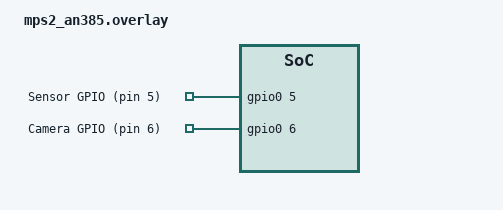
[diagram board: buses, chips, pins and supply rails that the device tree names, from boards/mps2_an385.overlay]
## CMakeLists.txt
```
cmake_minimum_required(VERSION 3.13.1)

find_package(Zephyr REQUIRED HINTS $ENV{ZEPHYR_BASE})
project(embedded_systems_project)

target_sources(app PRIVATE
    src/main.c
    src/ipc.c
    src/sensors.c
    src/controller.c
    src/camera.c
    src/display_dummy.c
    src/input_thread.c
    tests/integration/vehicle_simulator.c
)
```

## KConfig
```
# Kconfig - Radar System Configuration

menu "Configuração de Sistema de Radar"

config RADAR_SENSOR_DISTANCE_MM
    int "Distância entre os sensores (MM)"
    default 500
    range 100 2000
    help
      Distancia entre os dois sensores magnéticos usados para calcular a velocidade.

config RADAR_SPEED_LIMIT_LIGHT_KMH
    int "Limite de velocidade para veículos leves (km/h)"
    default 60
    range 30 100
    help
      Velocidade máxima permitida para veículos leves (2 eixos).

config RADAR_SPEED_LIMIT_HEAVY_KMH
    int "Limite de Velocidade para veículos pesados (km/h)"
    default 40
    range 20 80
    help
      Velocidade máxima permitida para veículos pesados (3+ eixos).

config RADAR_WARNING_THRESHOLD_PERCENT
    int "Percentual de limite de velocidade que dispara o aviso"
    default 90
    range 80 99
    help
      Percentual de limite de velocidade que aciona o aviso amarelo na tela.

config RADAR_CAMERA_FAILURE_RATE_PERCENT
    int "Taxa de simulaçao de Falha da Camera (0-100%)"
    default 10
    range 0 100
    help
      Porcetagem de chance da camera simular uma falha.
```

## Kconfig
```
menu "Zephyr"
source "Kconfig.zephyr"


config RADAR_SENSOR_DISTANCE_MM
    int "Distância entre os sensores (MM)"
    default 500
    range 100 2000
    help
      Distancia entre os dois sensores magnéticos usados para calcular a velocidade.

config RADAR_SPEED_LIMIT_LIGHT_KMH
    int "Limite de velocidade para veículos leves (km/h)"
    default 110
    range 30 120
    help
      Velocidade máxima permitida para veículos leves (2 eixos).

config RADAR_SPEED_LIMIT_HEAVY_KMH
    int "Limite de Velocidade para veículos pesados (km/h)"
    default 95
    range 40 100
    help
      Velocidade máxima permitida para veículos pesados (3+ eixos).

config RADAR_WARNING_THRESHOLD_PERCENT
    int "Percentual de limite de velocidade que dispara o aviso"
    default 10
    range 0 100
    help
      Percentual de limite de velocidade que aciona o aviso amarelo na tela.

config RADAR_CAMERA_FAILURE_RATE_PERCENT
    int "Taxa de simulaçao de Falha da Camera (0-100%)"
    default 10
    range 0 100
    help
      Percentagem de chance da camera simular uma falha.

endmenu
```

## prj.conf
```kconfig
CONFIG_MAIN_STACK_SIZE=2048
CONFIG_SYSTEM_WORKQUEUE_STACK_SIZE=2048

CONFIG_LOG=y
CONFIG_LOG_MODE_MINIMAL=y

CONFIG_PRINTK=y

CONFIG_ASSERT=y

CONFIG_NEWLIB_LIBC=y
CONFIG_POLL=y

CONFIG_SERIAL=y
CONFIG_UART_CONSOLE=y

CONFIG_UART_ASYNC_API=y 

CONFIG_CONSOLE=y
CONFIG_CBPRINTF_FP_SUPPORT=y

CONFIG_RADAR_SENSOR_DISTANCE_MM=500
CONFIG_RADAR_SPEED_LIMIT_LIGHT_KMH=80
CONFIG_RADAR_SPEED_LIMIT_HEAVY_KMH=60
CONFIG_RADAR_WARNING_THRESHOLD_PERCENT=10
CONFIG_RADAR_CAMERA_FAILURE_RATE_PERCENT=10
```

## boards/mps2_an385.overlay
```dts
#include <zephyr/dt-bindings/gpio/gpio.h>

/ {
    aliases {
        sensorgpio = &sensor_node;
        cameragpio = &camera_node;
    };

    sensors {
        compatible = "gpio-keys";

        sensor_node: sensor_gpio0 {
            gpios = <&gpio0 5 (GPIO_ACTIVE_HIGH | GPIO_PULL_UP)>;
            label = "Sensor GPIO (pin 5)";
        };

        camera_node: camera_gpio0 {
            gpios = <&gpio0 6 (GPIO_ACTIVE_HIGH | GPIO_PULL_UP)>;
            label = "Camera GPIO (pin 6)";
        };
    };
};
```

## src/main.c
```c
#include <zephyr/kernel.h>
#include <zephyr/logging/log.h>

#include "ipc.h"
#include "sensors.h"
#include "controller.h"
#include "camera.h"     
#include "display_dummy.h" 
#include "../tests/integration/vehicle_simulator.h" 
#include "input_thread.h"    

LOG_MODULE_REGISTER(main_app, LOG_LEVEL_INF);


K_THREAD_DEFINE(sensors_thread_def, 1024, sensors_thread, NULL, NULL, NULL, 
                7, 0, 0);

K_THREAD_DEFINE(controller_thread_def, 2048, controller_thread, NULL, NULL, NULL,
                5, 0, 0);
                
K_THREAD_DEFINE(display_thread_def, 1024, display_dummy_thread, NULL, NULL, NULL,
                6, 0, 0);


int main(void)
{
    LOG_INF("========================================");
    LOG_INF(" Radar Eletrônico - Sistema Iniciado");
    LOG_INF(" Plataforma: mps2_an385 (QEMU)");
    LOG_INF("========================================");

    LOG_INF("Inicializando IPC...");
    ipc_init();  
    LOG_INF("IPC OK.");

    LOG_INF("Inicializando módulos...");

    sensors_init();
    controller_init();
    camera_init();
    display_dummy_init();

    LOG_INF("Todos os módulos foram inicializados.");

    vehicle_simulator_start(); 
    input_thread_start();

    LOG_INF("Sistema operacional ativo. Threads rodando.");
    
   
    while (1) {
        
        k_sleep(K_FOREVER);
    }

    return 0;
}
```

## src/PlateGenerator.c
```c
#include <stdio.h>
#include <stdlib.h>
#include <time.h>

int main()
{
    srand(time(NULL));
    
    char plate[8];
    char alphabet[26] = {'a','b','c','d','e','f','g','h','i','j','k','l','m','n','o','p','q','r','s','t','u','v','w','x','y','z'};

    for (int j = 0; j < 3; j++){
        int index = rand() % 26; 
        plate[j] = alphabet[index];
    }

    int num1 = rand() % 10; 
    plate[3] = num1 + '0'; 

    int index4 = rand() % 26;
    plate[4] = alphabet[index4];
    
    int num5 = rand() % 10;
    plate[5] = num5 + '0'; 
    
    int num6 = rand() % 10;
    plate[6] = num6 + '0';
    
    plate[7] = '\0'; 


        /*
        
        printf("Placa Mercosul Gerada (LLLNLNN): ");
         printf("%c%c%c %c%c%c%c\n", 
           plate[0], plate[1], plate[2], 
           plate[3], plate[4], plate[5], plate[6]);
        */

    return 0;
}
```

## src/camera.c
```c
#include "camera.h"
#include <zephyr/logging/log.h>
#include <zephyr/random/random.h>

LOG_MODULE_REGISTER(camera, LOG_LEVEL_INF);

void camera_init(void)
{
    LOG_INF("Camera inicializada (falha simulada = %d%%)",
            CONFIG_RADAR_CAMERA_FAILURE_RATE_PERCENT);
}

bool camera_process_frame(void)
{
    uint8_t sorte = sys_rand32_get() % 100;

    if (sorte < CONFIG_RADAR_CAMERA_FAILURE_RATE_PERCENT) {
        LOG_WRN("Falha simulada da câmera!");
        return false;
    }

    LOG_INF("Frame capturado com sucesso.");
    return true;
}

void camera_thread(void *a, void *b, void *c)
{
    ARG_UNUSED(a); ARG_UNUSED(b); ARG_UNUSED(c);

    LOG_INF("Thread da câmera iniciada.");

    while (1) {
        camera_process_frame();
        k_sleep(K_SECONDS(2));
    }
}
```

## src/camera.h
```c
#ifndef CAMERA_H
#define CAMERA_H

#include <zephyr/kernel.h>
#include <zephyr/sys/util.h>
#include <stdbool.h>

void camera_init(void);
bool camera_process_frame(void);   
void camera_thread(void *, void *, void *);

#endif
```

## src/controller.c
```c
#include "controller.h"
#include "sensors.h"
#include "ipc.h"                 
#include "../tests/integration/vehicle_simulator.h"   
#include "display_dummy.h"       
#include <zephyr/logging/log.h>
#include <stdio.h>              


LOG_MODULE_REGISTER(controller, LOG_LEVEL_INF);


void controller_init(void)
{
    LOG_INF("Controller inicializado.");
}

float controller_calcula_velocidade_kmh(uint32_t tempo_ms)
{
    if (tempo_ms == 0) return 0.0f;

    float distancia_m = CONFIG_RADAR_SENSOR_DISTANCE_MM / 1000.0f;
    float tempo_s = tempo_ms / 1000.0f;

    float v_mps = distancia_m / tempo_s;
    float v_kmh = v_mps * 3.6f;
    return v_kmh;
}

tipo_veiculo_t controller_classifica_eixos(uint8_t num_eixos)
{
    if (num_eixos <= 2) return VEICULO_LEVE;
    return VEICULO_PESADO;
}

status_t controller_avalia_velocidade(float vel_kmh, tipo_veiculo_t tipo)
{
    float limite = (tipo == VEICULO_LEVE)
        ? CONFIG_RADAR_SPEED_LIMIT_LIGHT_KMH
        : CONFIG_RADAR_SPEED_LIMIT_HEAVY_KMH;

    float tolerancia = limite * (CONFIG_RADAR_WARNING_THRESHOLD_PERCENT / 100.0f);
    float limite_amarelo = limite + tolerancia;

    if (vel_kmh > limite)
    {
        if (vel_kmh <= limite_amarelo)
            return STATUS_AMARELO;

        return STATUS_VERMELHO;
    }

    return STATUS_VERDE;
}


void controller_thread(void *a, void *b, void *c)
{
    ARG_UNUSED(a);
    ARG_UNUSED(b);
    ARG_UNUSED(c);

    LOG_INF("Thread do controller iniciada. Aguardando dados/eventos...");

    struct sensor_msg sensor_msg;
    ipc_msg_t event_msg;
    ipc_msg_t camera_msg; 

    struct k_poll_event events[] = {
        K_POLL_EVENT_INITIALIZER(K_POLL_TYPE_MSGQ_DATA_AVAILABLE, K_POLL_MODE_NOTIFY_ONLY, &sensor_to_controller_msgq),
        K_POLL_EVENT_INITIALIZER(K_POLL_TYPE_MSGQ_DATA_AVAILABLE, K_POLL_MODE_NOTIFY_ONLY, &event_to_controller_msgq),
        K_POLL_EVENT_INITIALIZER(K_POLL_TYPE_MSGQ_DATA_AVAILABLE, K_POLL_MODE_NOTIFY_ONLY, &camera_to_controller_msgq)
    };

    while (1) {
        int ret = k_poll(events, ARRAY_SIZE(events), K_FOREVER);
        
        if (ret < 0) {
            LOG_ERR("Erro no k_poll: %d", ret);
            continue;
        }

        if (events[1].state == K_POLL_STATE_MSGQ_DATA_AVAILABLE) {
            if (k_msgq_get(&event_to_controller_msgq, &event_msg, K_NO_WAIT) == 0) { 

                if (event_msg.type == IPC_EVT_VEHICLE_REQUEST) {
                    
                    LOG_INF("EVENTO: Novo Veículo Acionado pelo Teclado. ID: %d", event_msg.data);

                    vehicle_simulator_press_enter(); 
                    
                    const char* new_plate = vehicle_simulator_generate();
                    
                    char display_text[64];
                    snprintf(display_text, sizeof(display_text), "SIMULATOR TRIGGERED. PLATE: %s", new_plate);
                    display_dummy_show_text(display_text); 
                }
            }
        }


        if (events[0].state == K_POLL_STATE_MSGQ_DATA_AVAILABLE) {
            if (k_msgq_get(&sensor_to_controller_msgq, &sensor_msg, K_NO_WAIT) == 0) {
                
                float vel = controller_calcula_velocidade_kmh(sensor_msg.tempo_ms);
                tipo_veiculo_t tipo = controller_classifica_eixos(sensor_msg.num_eixos);
                status_t status = controller_avalia_velocidade(vel, tipo);
                
                struct display_msg disp_msg = {
                    .vel_kmh = vel,
                    .tipo = tipo,
                    .status = status
                };
                
                if (k_msgq_put(&controller_to_display_msgq, &disp_msg, K_MSEC(50)) != 0) {
                    LOG_ERR("Falha ao enviar mensagem para o Display Dummy!");
                }
                
            
            }

        }

        
        if (events[2].state == K_POLL_STATE_MSGQ_DATA_AVAILABLE) {
            if (k_msgq_get(&camera_to_controller_msgq, &camera_msg, K_NO_WAIT) == 0) {
               
                // Aqui entraria a lógica de Reconhecimento de Placa ou processamento de imagem
                LOG_INF("CAMERA: Nova mensagem recebida. Iniciando processamento de placa...");
                
            }
        }

        for (size_t i = 0; i < ARRAY_SIZE(events); i++) {
            events[i].state = K_POLL_STATE_NOT_READY;
        }
    }
}
```

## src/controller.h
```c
#ifndef CONTROLLER_H
#define CONTROLLER_H

#include <zephyr/kernel.h>
#include <stdbool.h>
#include "ipc.h"
#include "sensors.h"


typedef enum {
    VEICULO_LEVE = 0,
    VEICULO_PESADO = 1
} tipo_veiculo_t;

typedef enum {
    STATUS_VERDE = 0,
    STATUS_AMARELO,
    STATUS_VERMELHO
} status_t;

void controller_init(void);
float controller_calcula_velocidade_kmh(uint32_t tempo_ms);
tipo_veiculo_t controller_classifica_eixos(uint8_t num_eixos);
status_t controller_avalia_velocidade(float vel_kmh, tipo_veiculo_t tipo);
void controller_thread(void *, void *, void *);

#endif
```

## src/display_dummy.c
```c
#include "display_dummy.h"
#include <zephyr/logging/log.h>
#include <zephyr/kernel.h>
#include "ipc.h"   
#include "controller.h" 

LOG_MODULE_REGISTER(display_dummy, LOG_LEVEL_INF);

#define ANSI_RESET   "\033[0m"
#define ANSI_GREEN   "\033[32m"
#define ANSI_YELLOW  "\033[33m"
#define ANSI_RED     "\033[31m"
#define ANSI_CYAN    "\033[36m" 

extern struct k_msgq controller_to_display_msgq;


void display_dummy_init(void)
{
    LOG_INF("Display Dummy inicializado (console).");
}

void display_dummy_show(float vel_kmh, tipo_veiculo_t tipo, status_t status)
{
    const char *cor;
    const char *status_txt;

    switch (status) {
    case STATUS_VERDE:
        cor = ANSI_GREEN;
        status_txt = "OK";
        break;
    case STATUS_AMARELO:
        cor = ANSI_YELLOW;
        status_txt = "ATENÇÃO";
        break;
    default:
        cor = ANSI_RED;
        status_txt = "INFRAÇÃO";
        break;
    }

    const char *tipo_txt = (tipo == VEICULO_LEVE) ? "LEVE" : "PESADO";

    printk("\n%s====================== RADAR ======================%s\n",
           cor, ANSI_RESET);

    printk("%sVelocidade: %.2f km/h%s\n", cor, (double)vel_kmh, ANSI_RESET);
    printk("%sTipo: %s%s\n", cor, tipo_txt, ANSI_RESET);
    printk("%sStatus: %s%s\n", cor, status_txt, ANSI_RESET);

    printk("%s==================================================%s\n",
           cor, ANSI_RESET);
}

void display_dummy_show_text(const char *text)
{
    printk("%s--- SIMULAÇÃO DE EVENTO ---%s\n", ANSI_CYAN, ANSI_RESET);
    printk("%s> %s%s\n", ANSI_CYAN, text, ANSI_RESET);
    printk("%s---------------------------%s\n", ANSI_CYAN, ANSI_RESET);
}

void display_dummy_thread(void *a, void *b, void *c)
{
    ARG_UNUSED(a); ARG_UNUSED(b); ARG_UNUSED(c);

    LOG_INF("Thread do display iniciada.");

    struct display_msg msg; 

    while (1) {
        k_msgq_get(&controller_to_display_msgq, &msg, K_FOREVER); 
        
        display_dummy_show(msg.vel_kmh, msg.tipo, msg.status);
    }
}
```

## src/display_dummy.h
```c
#ifndef DISPLAY_DUMMY_H
#define DISPLAY_DUMMY_H

#include "controller.h" 

struct display_msg {
    float vel_kmh;
    tipo_veiculo_t tipo;
    status_t status;
};


void display_dummy_init(void);
void display_dummy_thread(void *a, void *b, void *c);
void display_dummy_show(float vel_kmh, tipo_veiculo_t tipo, status_t status);
void display_dummy_show_text(const char *text);

#endif 
```

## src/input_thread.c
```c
#include <zephyr/kernel.h>
#include <zephyr/sys/printk.h>
#include <zephyr/drivers/uart.h>
#include <zephyr/device.h>    
#include "input_thread.h"
#include "ipc.h" 

const struct device *const console_dev = DEVICE_DT_GET(DT_CHOSEN(zephyr_console));

extern int ipc_send_event(ipc_msg_t *msg); 


static void input_thread_fn(void *a, void *b, void *c)
{
    ARG_UNUSED(a); ARG_UNUSED(b); ARG_UNUSED(c);

    if (!device_is_ready(console_dev)) {
        printk("Input Thread ERROR: Console device not ready!\n");
        return;
    }

    printk("Input Thread: Aguardando 'Enter' para simular novo veiculo...\n");

    while (1)
    {
        unsigned char c;
        if (uart_poll_in(console_dev, &c) == 0) {
            
            if (c == '\n' || c == '\r') {
                
                printk("Input Thread: ENTER Pressionado! Acionando simulador...\n");

               
                ipc_msg_t msg = {
                    .type = IPC_EVT_VEHICLE_REQUEST, 
                    .data = k_uptime_get_32() 
                };

                int ret = ipc_send_event(&msg);
                
                if (ret != 0) {
                    printk("Input Thread ERROR: Falha ao enviar evento (%d). Fila cheia?\n", ret);
                }
            } else {
                uart_poll_out(console_dev, c); 
            }
        }
        
        k_msleep(10); 
    }
}


K_THREAD_STACK_DEFINE(input_stack, 1024);
static struct k_thread input_thread_data;

void input_thread_start(void)
{
    k_thread_create(
        &input_thread_data,
        input_stack, K_THREAD_STACK_SIZEOF(input_stack),
        input_thread_fn,
        NULL, NULL, NULL,
        7, 0, K_NO_WAIT
    );
    k_thread_name_set(&input_thread_data, "input_thread");
}

void input_thread_stop(void) {
    k_thread_abort(&input_thread_data);
}
```

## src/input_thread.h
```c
#ifndef INPUT_THREAD_H
#define INPUT_THREAD_H

void input_thread_start(void);
void input_thread_stop(void);
void input_thread_set_callback(void (*cb)(void));

#endif 
```

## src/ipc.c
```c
#include "ipc.h"
#include <zephyr/kernel.h>
#include <zephyr/sys/printk.h>

#define IPC_QUEUE_LEN 8 

static ipc_msg_t event_to_controller_buffer[IPC_QUEUE_LEN];
struct k_msgq event_to_controller_msgq; 
static ipc_msg_t sensor_to_controller_buffer[IPC_QUEUE_LEN];
static ipc_msg_t camera_to_controller_buffer[IPC_QUEUE_LEN];
static ipc_msg_t controller_to_display_buffer[IPC_QUEUE_LEN];

struct k_msgq sensor_to_controller_msgq;
struct k_msgq camera_to_controller_msgq;
struct k_msgq controller_to_display_msgq;


void ipc_init(void)
{
    printk("[IPC] Inicializando canais IPC...\n");

    k_msgq_init(&event_to_controller_msgq,
                (char *)event_to_controller_buffer,
                sizeof(ipc_msg_t),
                IPC_QUEUE_LEN);

    k_msgq_init(&sensor_to_controller_msgq,
                (char *)sensor_to_controller_buffer,
                sizeof(ipc_msg_t),
                IPC_QUEUE_LEN);

    k_msgq_init(&camera_to_controller_msgq,
                (char *)camera_to_controller_buffer,
                sizeof(ipc_msg_t),
                IPC_QUEUE_LEN);

    k_msgq_init(&controller_to_display_msgq,
                (char *)controller_to_display_buffer,
                sizeof(ipc_msg_t),
                IPC_QUEUE_LEN);

    printk("[IPC] Message queues prontas.\n");
}



int ipc_send_event(ipc_msg_t *msg)
{
    return k_msgq_put(&event_to_controller_msgq, msg, K_NO_WAIT);
}

int ipc_receive_event(ipc_msg_t *msg, k_timeout_t timeout)
{
    return k_msgq_get(&event_to_controller_msgq, msg, timeout);
}


struct k_msgq *get_sensor_msgq(void)
{
    return &sensor_to_controller_msgq;
}
struct k_msgq *get_camera_msgq(void)
{
    return &camera_to_controller_msgq;
}
struct k_msgq *get_display_msgq(void)
{
    return &controller_to_display_msgq;
}
```

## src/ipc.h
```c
#ifndef IPC_H
#define IPC_H

#include <zephyr/kernel.h>
#include <stdint.h>

typedef enum {
    IPC_TYPE_SENSOR_DATA,      
    IPC_TYPE_CAMERA_DATA,      
    IPC_TYPE_DISPLAY_CMD,      
    IPC_EVT_VEHICLE_REQUEST,   
    IPC_EVT_SIMULATION_STOP    
} ipc_msg_type_t;

typedef struct {
    ipc_msg_type_t type;   
    uint32_t data;         
   
} ipc_msg_t;

extern struct k_msgq sensor_to_controller_msgq;
extern struct k_msgq camera_to_controller_msgq;
extern struct k_msgq controller_to_display_msgq;
extern struct k_msgq event_to_controller_msgq; 

void ipc_init(void);
struct k_msgq *get_sensor_msgq(void);
struct k_msgq *get_camera_msgq(void);
struct k_msgq *get_display_msgq(void);
int ipc_send_event(ipc_msg_t *msg);   
int ipc_receive_event(ipc_msg_t *msg, k_timeout_t timeout); 

#endif 
```

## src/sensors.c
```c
#include "sensors.h"
#include "ipc.h"
#include <zephyr/logging/log.h>
#include <zephyr/drivers/gpio.h>

extern struct k_msgq *get_sensor_msgq(void); 
extern struct k_msgq *get_camera_msgq(void); // Para o futuro

LOG_MODULE_REGISTER(sensors, LOG_LEVEL_INF);

static const struct gpio_dt_spec sensor_gpio =
    GPIO_DT_SPEC_GET(DT_ALIAS(sensorgpio), gpios);

static const struct gpio_dt_spec camera_gpio =
    GPIO_DT_SPEC_GET(DT_ALIAS(cameragpio), gpios);

static struct gpio_callback cb_sensor;
static struct gpio_callback cb_camera;

static uint32_t t_sensor = 0;
static uint32_t t_camera = 0;
static uint8_t contagem_eixos = 0;



static void sensor_isr(const struct device *dev,
                       struct gpio_callback *cb,
                       uint32_t pins)
{
    ARG_UNUSED(dev); ARG_UNUSED(cb); ARG_UNUSED(pins);

    t_sensor = k_uptime_get_32();
    contagem_eixos = 1;
    
    LOG_DBG("Sensor 1 Ativado. Tempo inicial: %d", t_sensor);
}


static void camera_isr(const struct device *dev,
                       struct gpio_callback *cb,
                       uint32_t pins)
{
    ARG_UNUSED(dev); ARG_UNUSED(cb); ARG_UNUSED(pins);

    t_camera = k_uptime_get_32();
    
  
    contagem_eixos++; 

    struct sensor_msg msg;
    msg.num_eixos = contagem_eixos;
    
    msg.tempo_ms = (t_camera >= t_sensor) ? (t_camera - t_sensor) : 0;
    
    struct k_msgq *q = get_sensor_msgq(); 
    if (q) {
        int ret = k_msgq_put(q, &msg, K_NO_WAIT);
        if (ret != 0) {
            LOG_ERR("ERRO: Falha ao enviar msg do sensor na ISR (%d).", ret);
        } else {
            LOG_DBG("Sensor: Msg enviada. Eixos=%d, Tempo=%dms", msg.num_eixos, msg.tempo_ms);
        }
    }

    contagem_eixos = 0;  
}

void sensors_init(void)
{
    if (!device_is_ready(sensor_gpio.port) ||
        !device_is_ready(camera_gpio.port)) {
        LOG_ERR("GPIO dos sensores/câmera não está pronto!");
        return;
    }

    /* Configura pinos */
    gpio_pin_configure_dt(&sensor_gpio, GPIO_INPUT | GPIO_PULL_UP);
    gpio_pin_configure_dt(&camera_gpio, GPIO_INPUT | GPIO_PULL_UP);

    /* Interrupções */
    gpio_pin_interrupt_configure_dt(&sensor_gpio, GPIO_INT_EDGE_TO_ACTIVE);
    gpio_pin_interrupt_configure_dt(&camera_gpio, GPIO_INT_EDGE_TO_ACTIVE);

    /* Registra callbacks */
    gpio_init_callback(&cb_sensor, sensor_isr, BIT(sensor_gpio.pin));
    gpio_init_callback(&cb_camera, camera_isr, BIT(camera_gpio.pin));

    gpio_add_callback(sensor_gpio.port, &cb_sensor);
    gpio_add_callback(camera_gpio.port, &cb_camera);

    LOG_INF("Sensores inicializados (sensor=%d, camera=%d)",
            sensor_gpio.pin, camera_gpio.pin);
}

                                    
void sensors_thread(void *a, void *b, void *c)
{
    ARG_UNUSED(a); ARG_UNUSED(b); ARG_UNUSED(c);

    LOG_INF("Thread de sensores iniciada. Atividade principal em ISR.");
    while (1) {
        k_sleep(K_SECONDS(30)); 
    }
}
```
